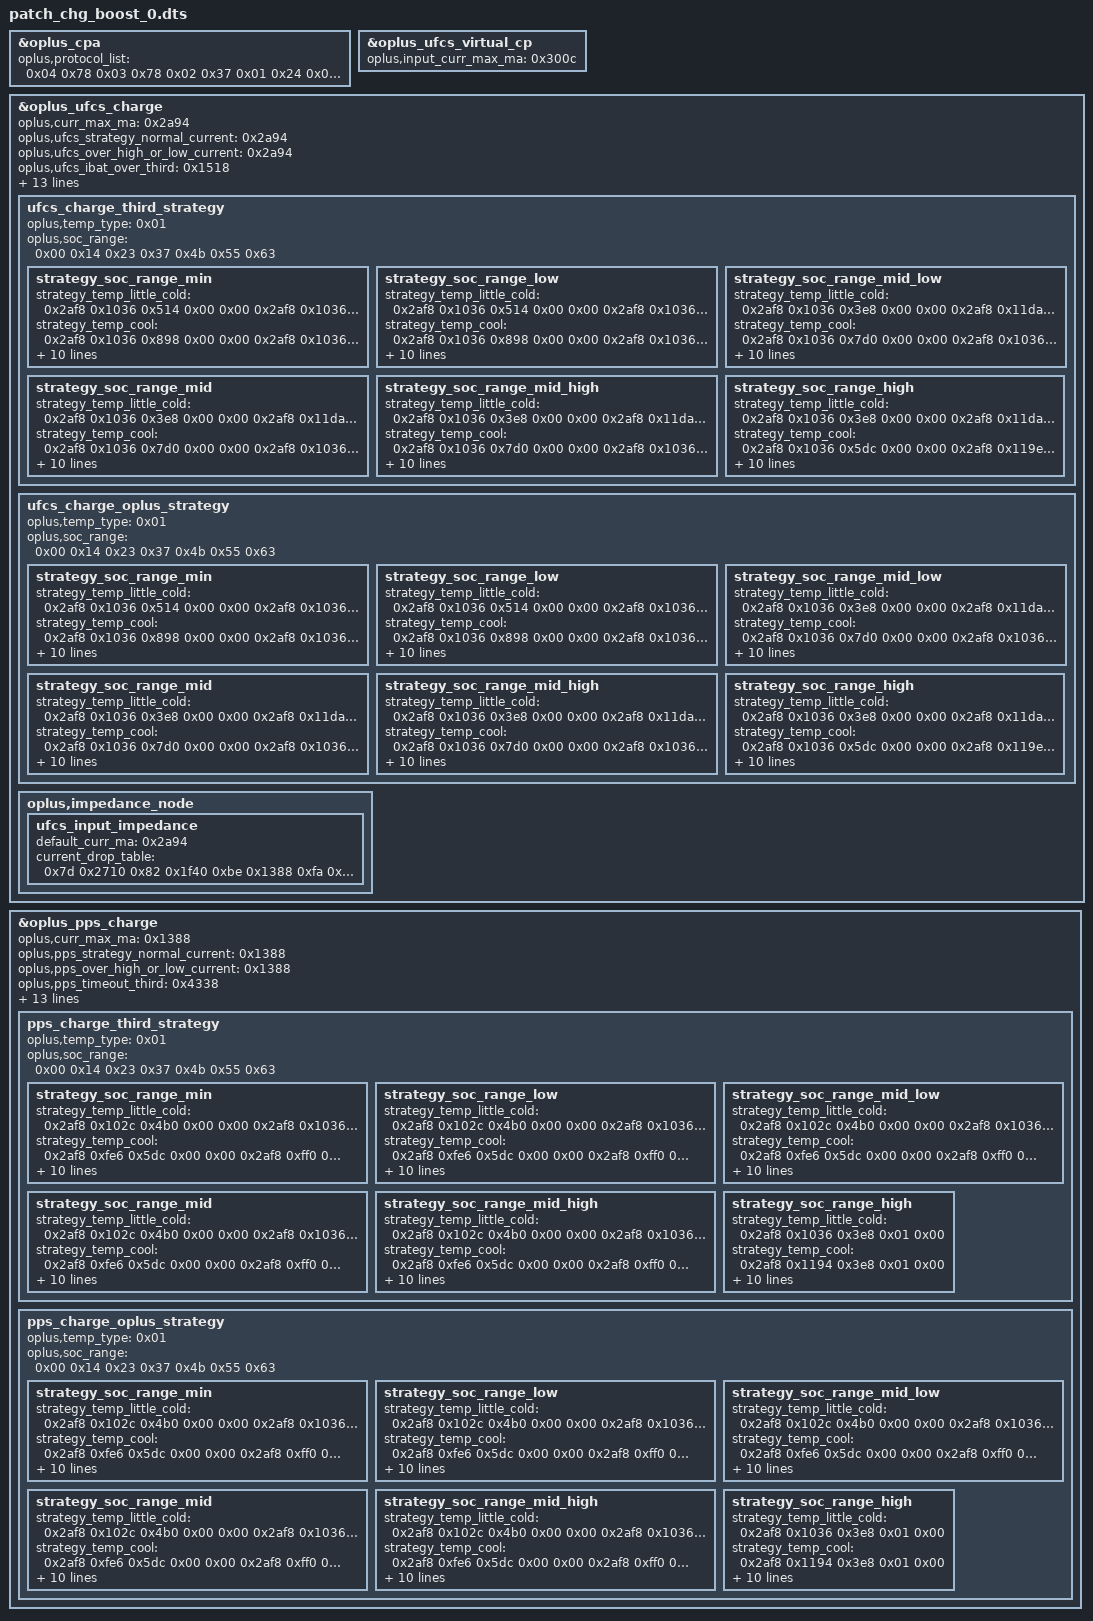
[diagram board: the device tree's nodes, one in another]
/dts-v1/;
/plugin/;

/ {
	fragment@0 {
		target = <&oplus_cpa>;
		__overlay__ {
			oplus,protocol_list = <0x04 0x78 0x03 0x78 0x02 0x37 0x01 0x24 0x05 0x24>;
		};
	};
	
	fragment@1 {
		target = <&oplus_ufcs_virtual_cp>;
		__overlay__ {
			oplus,input_curr_max_ma = <0x300c>;
		};
	};
	
	fragment@2 {
		target = <&oplus_ufcs_charge>;
		__overlay__ {
			oplus,curr_max_ma = <0x2a94>;
			oplus,ufcs_strategy_normal_current = <0x2a94>;
			oplus,ufcs_over_high_or_low_current = <0x2a94>;
			oplus,ufcs_ibat_over_third = <0x1518>;
			oplus,ufcs_ibat_over_oplus = <0x300c>;
			oplus,ufcs_ibus_over_oplus = <0x300c>;
			oplus,ufcs_full_cool_sw_vbat = <0x11da>;
			oplus,ufcs_full_normal_sw_vbat = <0x11da>;
			oplus,ufcs_full_normal_hw_vbat = <0x11e4>;
			oplus,ufcs_full_cool_sw_vbat_third = <0x1194>;
			oplus,ufcs_full_normal_sw_vbat_third = <0x11a8>;
			oplus,ufcs_full_normal_hw_vbat_third = <0x11d0>;
			oplus_spec,ufcs_high_soc = <0x63>;
			oplus,ufcs_strategy_high_current = <0x157c 0xdac 0x7d0 0x2a94 0x157c 0xdac>;
			oplus,ufcs_charge_strategy_soc = <0x00 0x14 0x23 0x37 0x4b 0x55 0x63>;
			
			ufcs_charge_third_strategy {
				oplus,temp_type = <0x01>;
				oplus,soc_range = <0x00 0x14 0x23 0x37 0x4b 0x55 0x63>;
				
				strategy_soc_range_min {
					strategy_temp_little_cold = <0x2af8 0x1036 0x514 0x00 0x00 0x2af8 0x1036 0x3e8 0x00 0x00 0x2af8 0x11da 0x1f4 0x01 0x00>;
					strategy_temp_cool = <0x2af8 0x1036 0x898 0x00 0x00 0x2af8 0x1036 0x7d0 0x00 0x00 0x2af8 0x1036 0x5dc 0x00 0x00 0x2af8 0x119e 0x514 0x00 0x00 0x2af8 0x119e 0x3e8 0x00 0x00 0x2af8 0x11d0 0x2bc 0x00 0x00 0x2af8 0x11da 0x258 0x01 0x00>;
					strategy_temp_little_cool = <0x2af8 0x1036 0xb54 0x00 0x00 0x2af8 0x1036 0x9c4 0x00 0x00 0x2af8 0x10ea 0x898 0x00 0x00 0x2af8 0x10ea 0x7d0 0x00 0x00 0x2af8 0x10ea 0x5dc 0x00 0x00 0x2af8 0x11d0 0x514 0x00 0x00 0x2af8 0x11d0 0x3e8 0x00 0x00 0x2af8 0x11da 0x2bc 0x01 0x00>;
					strategy_temp_little_cool_high = <0x2af8 0x1036 0x16a8 0x00 0x3c 0x2af8 0x1036 0x157c 0x00 0x00 0x2af8 0x1036 0x1388 0x00 0x00 0x2af8 0x1036 0x1194 0x00 0x00 0x2af8 0x10b8 0x10cc 0x00 0x00 0x2af8 0x10b8 0xfa0 0x00 0x00 0x2af8 0x10b8 0xdac 0x00 0x00 0x2af8 0x119e 0xd48 0x00 0x00 0x2af8 0x119e 0xbb8 0x00 0x00 0x2af8 0x11d0 0xb54 0x00 0x00 0x2af8 0x11d0 0x9c4 0x00 0x00 0x2af8 0x11d0 0x7d0 0x00 0x00 0x2af8 0x11d0 0x5dc 0x00 0x00 0x2af8 0x11d0 0x3e8 0x00 0x00 0x2af8 0x11da 0x384 0x01 0x00>;
					strategy_temp_normal_low = <0x2af8 0x1004 0x2a94 0x00 0xa 0x2af8 0x1004 0x238c 0x00 0x32 0x2af8 0x102c 0x21fc 0x00 0x00 0x2af8 0x102c 0x2134 0x00 0x00 0x2af8 0x102c 0x1f40 0x00 0x00 0x2af8 0x1086 0x1e78 0x00 0x00 0x2af8 0x1086 0x1d4c 0x00 0x00 0x2af8 0x1086 0x1b58 0x00 0x00 0x2af8 0x1086 0x1964 0x00 0x00 0x2af8 0x1086 0x1770 0x00 0x00 0x2af8 0x114e 0x16a8 0x00 0x00 0x2af8 0x114e 0x157c 0x00 0x00 0x2af8 0x114e 0x1388 0x00 0x00 0x2af8 0x114e 0x1194 0x00 0x00 0x2af8 0x114e 0xfa0 0x00 0x00 0x2af8 0x114e 0xdac 0x00 0x00 0x2af8 0x11d0 0xd48 0x00 0x00 0x2af8 0x11d0 0xbb8 0x00 0x00 0x2af8 0x11d0 0x9c4 0x00 0x00 0x2af8 0x11d0 0x7d0 0x00 0x00 0x2af8 0x11da 0x5dc 0x01 0x00>;
					strategy_temp_normal_high = <0x2af8 0x1004 0x2a94 0x00 0xa 0x2af8 0x1004 0x238c 0x00 0x32 0x2af8 0x102c 0x21fc 0x00 0x00 0x2af8 0x102c 0x2134 0x00 0x00 0x2af8 0x102c 0x1f40 0x00 0x00 0x2af8 0x1086 0x1e78 0x00 0x00 0x2af8 0x1086 0x1d4c 0x00 0x00 0x2af8 0x1086 0x1b58 0x00 0x00 0x2af8 0x1086 0x1964 0x00 0x00 0x2af8 0x1086 0x1770 0x00 0x00 0x2af8 0x114e 0x16a8 0x00 0x00 0x2af8 0x114e 0x157c 0x00 0x00 0x2af8 0x114e 0x1388 0x00 0x00 0x2af8 0x114e 0x1194 0x00 0x00 0x2af8 0x114e 0xfa0 0x00 0x00 0x2af8 0x114e 0xdac 0x00 0x00 0x2af8 0x11d0 0xd48 0x00 0x00 0x2af8 0x11d0 0xbb8 0x00 0x00 0x2af8 0x11d0 0x9c4 0x00 0x00 0x2af8 0x11da 0x960 0x01 0x00>;
					strategy_temp_warm = <0x2af8 0x1018 0x640 0x00 0x00 0x2af8 0x1018 0x5dc 0x00 0x00 0x2af8 0x1018 0x3e8 0x00 0x00 0x2af8 0x1022 0x1f4 0x01 0x00>;
				};
				
				strategy_soc_range_low {
					strategy_temp_little_cold = <0x2af8 0x1036 0x514 0x00 0x00 0x2af8 0x1036 0x3e8 0x00 0x00 0x2af8 0x11da 0x1f4 0x01 0x00>;
					strategy_temp_cool = <0x2af8 0x1036 0x898 0x00 0x00 0x2af8 0x1036 0x7d0 0x00 0x00 0x2af8 0x1036 0x5dc 0x00 0x00 0x2af8 0x119e 0x514 0x00 0x00 0x2af8 0x119e 0x3e8 0x00 0x00 0x2af8 0x11d0 0x2bc 0x00 0x00 0x2af8 0x11da 0x258 0x01 0x00>;
					strategy_temp_little_cool = <0x2af8 0x1036 0xb54 0x00 0x00 0x2af8 0x1036 0x9c4 0x00 0x00 0x2af8 0x10ea 0x898 0x00 0x00 0x2af8 0x10ea 0x7d0 0x00 0x00 0x2af8 0x10ea 0x5dc 0x00 0x00 0x2af8 0x11d0 0x514 0x00 0x00 0x2af8 0x11d0 0x3e8 0x00 0x00 0x2af8 0x11da 0x2bc 0x01 0x00>;
					strategy_temp_little_cool_high = <0x2af8 0x1036 0x16a8 0x00 0x3c 0x2af8 0x1036 0x157c 0x00 0x00 0x2af8 0x1036 0x1388 0x00 0x00 0x2af8 0x1036 0x1194 0x00 0x00 0x2af8 0x10b8 0x10cc 0x00 0x00 0x2af8 0x10b8 0xfa0 0x00 0x00 0x2af8 0x10b8 0xdac 0x00 0x00 0x2af8 0x119e 0xd48 0x00 0x00 0x2af8 0x119e 0xbb8 0x00 0x00 0x2af8 0x11d0 0xb54 0x00 0x00 0x2af8 0x11d0 0x9c4 0x00 0x00 0x2af8 0x11d0 0x7d0 0x00 0x00 0x2af8 0x11d0 0x5dc 0x00 0x00 0x2af8 0x11d0 0x3e8 0x00 0x00 0x2af8 0x11da 0x384 0x01 0x00>;
					strategy_temp_normal_low = <0x2af8 0x1004 0x238c 0x00 0x3c 0x2af8 0x102c 0x21fc 0x00 0x00 0x2af8 0x102c 0x2134 0x00 0x00 0x2af8 0x102c 0x1f40 0x00 0x00 0x2af8 0x1086 0x1e78 0x00 0x00 0x2af8 0x1086 0x1d4c 0x00 0x00 0x2af8 0x1086 0x1b58 0x00 0x00 0x2af8 0x1086 0x1964 0x00 0x00 0x2af8 0x1086 0x1770 0x00 0x00 0x2af8 0x114e 0x16a8 0x00 0x00 0x2af8 0x114e 0x157c 0x00 0x00 0x2af8 0x114e 0x1388 0x00 0x00 0x2af8 0x114e 0x1194 0x00 0x00 0x2af8 0x114e 0xfa0 0x00 0x00 0x2af8 0x114e 0xdac 0x00 0x00 0x2af8 0x11d0 0xd48 0x00 0x00 0x2af8 0x11d0 0xbb8 0x00 0x00 0x2af8 0x11d0 0x9c4 0x00 0x00 0x2af8 0x11d0 0x7d0 0x00 0x00 0x2af8 0x11da 0x5dc 0x01 0x00>;
					strategy_temp_normal_high = <0x2af8 0x1004 0x238c 0x00 0x3c 0x2af8 0x102c 0x21fc 0x00 0x00 0x2af8 0x102c 0x2134 0x00 0x00 0x2af8 0x102c 0x1f40 0x00 0x00 0x2af8 0x1086 0x1e78 0x00 0x00 0x2af8 0x1086 0x1d4c 0x00 0x00 0x2af8 0x1086 0x1b58 0x00 0x00 0x2af8 0x1086 0x1964 0x00 0x00 0x2af8 0x1086 0x1770 0x00 0x00 0x2af8 0x114e 0x16a8 0x00 0x00 0x2af8 0x114e 0x157c 0x00 0x00 0x2af8 0x114e 0x1388 0x00 0x00 0x2af8 0x114e 0x1194 0x00 0x00 0x2af8 0x114e 0xfa0 0x00 0x00 0x2af8 0x114e 0xdac 0x00 0x00 0x2af8 0x11d0 0xd48 0x00 0x00 0x2af8 0x11d0 0xbb8 0x00 0x00 0x2af8 0x11d0 0x9c4 0x00 0x00 0x2af8 0x11da 0x960 0x01 0x00>;
					strategy_temp_warm = <0x2af8 0x1018 0x640 0x00 0x00 0x2af8 0x1018 0x5dc 0x00 0x00 0x2af8 0x1018 0x3e8 0x00 0x00 0x2af8 0x1022 0x1f4 0x01 0x00>;
				};
				
				strategy_soc_range_mid_low {
					strategy_temp_little_cold = <0x2af8 0x1036 0x3e8 0x00 0x00 0x2af8 0x11da 0x1f4 0x01 0x00>;
					strategy_temp_cool = <0x2af8 0x1036 0x7d0 0x00 0x00 0x2af8 0x1036 0x5dc 0x00 0x00 0x2af8 0x119e 0x514 0x00 0x00 0x2af8 0x119e 0x3e8 0x00 0x00 0x2af8 0x11d0 0x2bc 0x00 0x00 0x2af8 0x11da 0x258 0x01 0x00>;
					strategy_temp_little_cool = <0x2af8 0x1036 0xb54 0x00 0x00 0x2af8 0x1036 0x9c4 0x00 0x00 0x2af8 0x10ea 0x898 0x00 0x00 0x2af8 0x10ea 0x7d0 0x00 0x00 0x2af8 0x10ea 0x5dc 0x00 0x00 0x2af8 0x11d0 0x514 0x00 0x00 0x2af8 0x11d0 0x3e8 0x00 0x00 0x2af8 0x11da 0x2bc 0x01 0x00>;
					strategy_temp_little_cool_high = <0x2af8 0x1036 0x16a8 0x00 0x3c 0x2af8 0x1036 0x157c 0x00 0x00 0x2af8 0x1036 0x1388 0x00 0x00 0x2af8 0x1036 0x1194 0x00 0x00 0x2af8 0x10b8 0x10cc 0x00 0x00 0x2af8 0x10b8 0xfa0 0x00 0x00 0x2af8 0x10b8 0xdac 0x00 0x00 0x2af8 0x119e 0xd48 0x00 0x00 0x2af8 0x119e 0xbb8 0x00 0x00 0x2af8 0x11d0 0xb54 0x00 0x00 0x2af8 0x11d0 0x9c4 0x00 0x00 0x2af8 0x11d0 0x7d0 0x00 0x00 0x2af8 0x11d0 0x5dc 0x00 0x00 0x2af8 0x11d0 0x3e8 0x00 0x00 0x2af8 0x11da 0x384 0x01 0x00>;
					strategy_temp_normal_low = <0x2af8 0x1004 0x238c 0x00 0x3c 0x2af8 0x102c 0x21fc 0x00 0x00 0x2af8 0x102c 0x2134 0x00 0x00 0x2af8 0x102c 0x1f40 0x00 0x00 0x2af8 0x1086 0x1e78 0x00 0x00 0x2af8 0x1086 0x1d4c 0x00 0x00 0x2af8 0x1086 0x1b58 0x00 0x00 0x2af8 0x1086 0x1964 0x00 0x00 0x2af8 0x1086 0x1770 0x00 0x00 0x2af8 0x114e 0x16a8 0x00 0x00 0x2af8 0x114e 0x157c 0x00 0x00 0x2af8 0x114e 0x1388 0x00 0x00 0x2af8 0x114e 0x1194 0x00 0x00 0x2af8 0x114e 0xfa0 0x00 0x00 0x2af8 0x114e 0xdac 0x00 0x00 0x2af8 0x11d0 0xd48 0x00 0x00 0x2af8 0x11d0 0xbb8 0x00 0x00 0x2af8 0x11d0 0x9c4 0x00 0x00 0x2af8 0x11d0 0x7d0 0x00 0x00 0x2af8 0x11da 0x5dc 0x01 0x00>;
					strategy_temp_normal_high = <0x2af8 0x1004 0x238c 0x00 0x3c 0x2af8 0x102c 0x21fc 0x00 0x00 0x2af8 0x102c 0x2134 0x00 0x00 0x2af8 0x102c 0x1f40 0x00 0x00 0x2af8 0x1086 0x1e78 0x00 0x00 0x2af8 0x1086 0x1d4c 0x00 0x00 0x2af8 0x1086 0x1b58 0x00 0x00 0x2af8 0x1086 0x1964 0x00 0x00 0x2af8 0x1086 0x1770 0x00 0x00 0x2af8 0x114e 0x16a8 0x00 0x00 0x2af8 0x114e 0x157c 0x00 0x00 0x2af8 0x114e 0x1388 0x00 0x00 0x2af8 0x114e 0x1194 0x00 0x00 0x2af8 0x114e 0xfa0 0x00 0x00 0x2af8 0x114e 0xdac 0x00 0x00 0x2af8 0x11d0 0xd48 0x00 0x00 0x2af8 0x11d0 0xbb8 0x00 0x00 0x2af8 0x11d0 0x9c4 0x00 0x00 0x2af8 0x11da 0x960 0x01 0x00>;
					strategy_temp_warm = <0x2af8 0x1018 0x640 0x00 0x00 0x2af8 0x1018 0x5dc 0x00 0x00 0x2af8 0x1018 0x3e8 0x00 0x00 0x2af8 0x1022 0x1f4 0x01 0x00>;
				};
				
				strategy_soc_range_mid {
					strategy_temp_little_cold = <0x2af8 0x1036 0x3e8 0x00 0x00 0x2af8 0x11da 0x1f4 0x01 0x00>;
					strategy_temp_cool = <0x2af8 0x1036 0x7d0 0x00 0x00 0x2af8 0x1036 0x5dc 0x00 0x00 0x2af8 0x119e 0x514 0x00 0x00 0x2af8 0x119e 0x3e8 0x00 0x00 0x2af8 0x11d0 0x2bc 0x00 0x00 0x2af8 0x11da 0x258 0x01 0x00>;
					strategy_temp_little_cool = <0x2af8 0x1036 0xb54 0x00 0x00 0x2af8 0x1036 0x9c4 0x00 0x00 0x2af8 0x10ea 0x898 0x00 0x00 0x2af8 0x10ea 0x7d0 0x00 0x00 0x2af8 0x10ea 0x5dc 0x00 0x00 0x2af8 0x11d0 0x514 0x00 0x00 0x2af8 0x11d0 0x3e8 0x00 0x00 0x2af8 0x11da 0x2bc 0x01 0x00>;
					strategy_temp_little_cool_high = <0x2af8 0x10b8 0xfa0 0x00 0x00 0x2af8 0x10b8 0xdac 0x00 0x00 0x2af8 0x119e 0xd48 0x00 0x00 0x2af8 0x119e 0xbb8 0x00 0x00 0x2af8 0x11d0 0xb54 0x00 0x00 0x2af8 0x11d0 0x9c4 0x00 0x00 0x2af8 0x11d0 0x7d0 0x00 0x00 0x2af8 0x11d0 0x5dc 0x00 0x00 0x2af8 0x11d0 0x3e8 0x00 0x00 0x2af8 0x11da 0x384 0x01 0x00>;
					strategy_temp_normal_low = <0x2af8 0x114e 0x1194 0x00 0x00 0x2af8 0x114e 0xfa0 0x00 0x00 0x2af8 0x114e 0xdac 0x00 0x00 0x2af8 0x11d0 0xd48 0x00 0x00 0x2af8 0x11d0 0xbb8 0x00 0x00 0x2af8 0x11d0 0x9c4 0x00 0x00 0x2af8 0x11d0 0x7d0 0x00 0x00 0x2af8 0x11da 0x5dc 0x01 0x00>;
					strategy_temp_normal_high = <0x2af8 0x114e 0x1388 0x00 0x00 0x2af8 0x114e 0x1194 0x00 0x00 0x2af8 0x114e 0xfa0 0x00 0x00 0x2af8 0x114e 0xdac 0x00 0x00 0x2af8 0x11d0 0xd48 0x00 0x00 0x2af8 0x11d0 0xbb8 0x00 0x00 0x2af8 0x11d0 0x9c4 0x00 0x00 0x2af8 0x11da 0x960 0x01 0x00>;
					strategy_temp_warm = <0x2af8 0x1022 0x3e8 0x01 0x00>;
				};
				
				strategy_soc_range_mid_high {
					strategy_temp_little_cold = <0x2af8 0x1036 0x3e8 0x00 0x00 0x2af8 0x11da 0x1f4 0x01 0x00>;
					strategy_temp_cool = <0x2af8 0x1036 0x7d0 0x00 0x00 0x2af8 0x1036 0x5dc 0x00 0x00 0x2af8 0x119e 0x514 0x00 0x00 0x2af8 0x119e 0x3e8 0x00 0x00 0x2af8 0x11d0 0x2bc 0x00 0x00 0x2af8 0x11da 0x258 0x01 0x00>;
					strategy_temp_little_cool = <0x2af8 0x1036 0xb54 0x00 0x00 0x2af8 0x1036 0x9c4 0x00 0x00 0x2af8 0x10ea 0x898 0x00 0x00 0x2af8 0x10ea 0x7d0 0x00 0x00 0x2af8 0x10ea 0x5dc 0x00 0x00 0x2af8 0x11d0 0x514 0x00 0x00 0x2af8 0x11d0 0x3e8 0x00 0x00 0x2af8 0x11da 0x2bc 0x01 0x00>;
					strategy_temp_little_cool_high = <0x2af8 0x119e 0xbb8 0x00 0x00 0x2af8 0x11d0 0xb54 0x00 0x00 0x2af8 0x11d0 0x9c4 0x00 0x00 0x2af8 0x11d0 0x7d0 0x00 0x00 0x2af8 0x11d0 0x5dc 0x00 0x00 0x2af8 0x11d0 0x3e8 0x00 0x00 0x2af8 0x11da 0x384 0x01 0x00>;
					strategy_temp_normal_low = <0x2af8 0x114e 0xdac 0x00 0x00 0x2af8 0x11d0 0xd48 0x00 0x00 0x2af8 0x11d0 0xbb8 0x00 0x00 0x2af8 0x11d0 0x9c4 0x00 0x00 0x2af8 0x11d0 0x7d0 0x00 0x00 0x2af8 0x11da 0x5dc 0x01 0x00>;
					strategy_temp_normal_high = <0x2af8 0x114e 0xdac 0x00 0x00 0x2af8 0x11d0 0xd48 0x00 0x00 0x2af8 0x11d0 0xbb8 0x00 0x00 0x2af8 0x11d0 0x9c4 0x00 0x00 0x2af8 0x11da 0x960 0x01 0x00>;
					strategy_temp_warm = <0x2af8 0x1022 0x3e8 0x01 0x00>;
				};
				
				strategy_soc_range_high {
					strategy_temp_little_cold = <0x2af8 0x1036 0x3e8 0x00 0x00 0x2af8 0x11da 0x1f4 0x01 0x00>;
					strategy_temp_cool = <0x2af8 0x1036 0x5dc 0x00 0x00 0x2af8 0x119e 0x514 0x00 0x00 0x2af8 0x119e 0x3e8 0x00 0x00 0x2af8 0x11d0 0x2bc 0x00 0x00 0x2af8 0x11da 0x258 0x01 0x00>;
					strategy_temp_little_cool = <0x2af8 0x10ea 0x5dc 0x00 0x00 0x2af8 0x11d0 0x514 0x00 0x00 0x2af8 0x11d0 0x3e8 0x00 0x00 0x2af8 0x11da 0x2bc 0x01 0x00>;
					strategy_temp_little_cool_high = <0x2af8 0x11d0 0x5dc 0x00 0x00 0x2af8 0x11d0 0x3e8 0x00 0x00 0x2af8 0x11da 0x384 0x01 0x00>;
					strategy_temp_normal_low = <0x2af8 0x11d0 0x7d0 0x00 0x00 0x2af8 0x11da 0x5dc 0x01 0x00>;
					strategy_temp_normal_high = <0x2af8 0x11da 0x960 0x01 0x00>;
					strategy_temp_warm = <0x2af8 0x1022 0x3e8 0x01 0x00>;
				};
			};
			
			ufcs_charge_oplus_strategy {
				oplus,temp_type = <0x01>;
				oplus,soc_range = <0x00 0x14 0x23 0x37 0x4b 0x55 0x63>;
				
				strategy_soc_range_min {
					strategy_temp_little_cold = <0x2af8 0x1036 0x514 0x00 0x00 0x2af8 0x1036 0x3e8 0x00 0x00 0x2af8 0x11da 0x1f4 0x01 0x00>;
					strategy_temp_cool = <0x2af8 0x1036 0x898 0x00 0x00 0x2af8 0x1036 0x7d0 0x00 0x00 0x2af8 0x1036 0x5dc 0x00 0x00 0x2af8 0x119e 0x514 0x00 0x00 0x2af8 0x119e 0x3e8 0x00 0x00 0x2af8 0x11d0 0x2bc 0x00 0x00 0x2af8 0x11da 0x258 0x01 0x00>;
					strategy_temp_little_cool = <0x2af8 0x1036 0xb54 0x00 0x00 0x2af8 0x1036 0x9c4 0x00 0x00 0x2af8 0x10ea 0x898 0x00 0x00 0x2af8 0x10ea 0x7d0 0x00 0x00 0x2af8 0x10ea 0x5dc 0x00 0x00 0x2af8 0x11d0 0x514 0x00 0x00 0x2af8 0x11d0 0x3e8 0x00 0x00 0x2af8 0x11da 0x2bc 0x01 0x00>;
					strategy_temp_little_cool_high = <0x2af8 0x1036 0x16a8 0x00 0x3c 0x2af8 0x1036 0x157c 0x00 0x00 0x2af8 0x1036 0x1388 0x00 0x00 0x2af8 0x1036 0x1194 0x00 0x00 0x2af8 0x10b8 0x10cc 0x00 0x00 0x2af8 0x10b8 0xfa0 0x00 0x00 0x2af8 0x10b8 0xdac 0x00 0x00 0x2af8 0x119e 0xd48 0x00 0x00 0x2af8 0x119e 0xbb8 0x00 0x00 0x2af8 0x11d0 0xb54 0x00 0x00 0x2af8 0x11d0 0x9c4 0x00 0x00 0x2af8 0x11d0 0x7d0 0x00 0x00 0x2af8 0x11d0 0x5dc 0x00 0x00 0x2af8 0x11d0 0x3e8 0x00 0x00 0x2af8 0x11da 0x384 0x01 0x00>;
					strategy_temp_normal_low = <0x2af8 0x1004 0x2a94 0x00 0xa 0x2af8 0x1004 0x238c 0x00 0x32 0x2af8 0x102c 0x21fc 0x00 0x00 0x2af8 0x102c 0x2134 0x00 0x00 0x2af8 0x102c 0x1f40 0x00 0x00 0x2af8 0x1086 0x1e78 0x00 0x00 0x2af8 0x1086 0x1d4c 0x00 0x00 0x2af8 0x1086 0x1b58 0x00 0x00 0x2af8 0x1086 0x1964 0x00 0x00 0x2af8 0x1086 0x1770 0x00 0x00 0x2af8 0x114e 0x16a8 0x00 0x00 0x2af8 0x114e 0x157c 0x00 0x00 0x2af8 0x114e 0x1388 0x00 0x00 0x2af8 0x114e 0x1194 0x00 0x00 0x2af8 0x114e 0xfa0 0x00 0x00 0x2af8 0x114e 0xdac 0x00 0x00 0x2af8 0x11d0 0xd48 0x00 0x00 0x2af8 0x11d0 0xbb8 0x00 0x00 0x2af8 0x11d0 0x9c4 0x00 0x00 0x2af8 0x11d0 0x7d0 0x00 0x00 0x2af8 0x11da 0x5dc 0x01 0x00>;
					strategy_temp_normal_high = <0x2af8 0x1004 0x2a94 0x00 0xa 0x2af8 0x1004 0x238c 0x00 0x32 0x2af8 0x102c 0x21fc 0x00 0x00 0x2af8 0x102c 0x2134 0x00 0x00 0x2af8 0x102c 0x1f40 0x00 0x00 0x2af8 0x1086 0x1e78 0x00 0x00 0x2af8 0x1086 0x1d4c 0x00 0x00 0x2af8 0x1086 0x1b58 0x00 0x00 0x2af8 0x1086 0x1964 0x00 0x00 0x2af8 0x1086 0x1770 0x00 0x00 0x2af8 0x114e 0x16a8 0x00 0x00 0x2af8 0x114e 0x157c 0x00 0x00 0x2af8 0x114e 0x1388 0x00 0x00 0x2af8 0x114e 0x1194 0x00 0x00 0x2af8 0x114e 0xfa0 0x00 0x00 0x2af8 0x114e 0xdac 0x00 0x00 0x2af8 0x11d0 0xd48 0x00 0x00 0x2af8 0x11d0 0xbb8 0x00 0x00 0x2af8 0x11d0 0x9c4 0x00 0x00 0x2af8 0x11da 0x960 0x01 0x00>;
					strategy_temp_warm = <0x2af8 0x1018 0x640 0x00 0x00 0x2af8 0x1018 0x5dc 0x00 0x00 0x2af8 0x1018 0x3e8 0x00 0x00 0x2af8 0x1022 0x1f4 0x01 0x00>;
				};
				
				strategy_soc_range_low {
					strategy_temp_little_cold = <0x2af8 0x1036 0x514 0x00 0x00 0x2af8 0x1036 0x3e8 0x00 0x00 0x2af8 0x11da 0x1f4 0x01 0x00>;
					strategy_temp_cool = <0x2af8 0x1036 0x898 0x00 0x00 0x2af8 0x1036 0x7d0 0x00 0x00 0x2af8 0x1036 0x5dc 0x00 0x00 0x2af8 0x119e 0x514 0x00 0x00 0x2af8 0x119e 0x3e8 0x00 0x00 0x2af8 0x11d0 0x2bc 0x00 0x00 0x2af8 0x11da 0x258 0x01 0x00>;
					strategy_temp_little_cool = <0x2af8 0x1036 0xb54 0x00 0x00 0x2af8 0x1036 0x9c4 0x00 0x00 0x2af8 0x10ea 0x898 0x00 0x00 0x2af8 0x10ea 0x7d0 0x00 0x00 0x2af8 0x10ea 0x5dc 0x00 0x00 0x2af8 0x11d0 0x514 0x00 0x00 0x2af8 0x11d0 0x3e8 0x00 0x00 0x2af8 0x11da 0x2bc 0x01 0x00>;
					strategy_temp_little_cool_high = <0x2af8 0x1036 0x16a8 0x00 0x3c 0x2af8 0x1036 0x157c 0x00 0x00 0x2af8 0x1036 0x1388 0x00 0x00 0x2af8 0x1036 0x1194 0x00 0x00 0x2af8 0x10b8 0x10cc 0x00 0x00 0x2af8 0x10b8 0xfa0 0x00 0x00 0x2af8 0x10b8 0xdac 0x00 0x00 0x2af8 0x119e 0xd48 0x00 0x00 0x2af8 0x119e 0xbb8 0x00 0x00 0x2af8 0x11d0 0xb54 0x00 0x00 0x2af8 0x11d0 0x9c4 0x00 0x00 0x2af8 0x11d0 0x7d0 0x00 0x00 0x2af8 0x11d0 0x5dc 0x00 0x00 0x2af8 0x11d0 0x3e8 0x00 0x00 0x2af8 0x11da 0x384 0x01 0x00>;
					strategy_temp_normal_low = <0x2af8 0x1004 0x238c 0x00 0x3c 0x2af8 0x102c 0x21fc 0x00 0x00 0x2af8 0x102c 0x2134 0x00 0x00 0x2af8 0x102c 0x1f40 0x00 0x00 0x2af8 0x1086 0x1e78 0x00 0x00 0x2af8 0x1086 0x1d4c 0x00 0x00 0x2af8 0x1086 0x1b58 0x00 0x00 0x2af8 0x1086 0x1964 0x00 0x00 0x2af8 0x1086 0x1770 0x00 0x00 0x2af8 0x114e 0x16a8 0x00 0x00 0x2af8 0x114e 0x157c 0x00 0x00 0x2af8 0x114e 0x1388 0x00 0x00 0x2af8 0x114e 0x1194 0x00 0x00 0x2af8 0x114e 0xfa0 0x00 0x00 0x2af8 0x114e 0xdac 0x00 0x00 0x2af8 0x11d0 0xd48 0x00 0x00 0x2af8 0x11d0 0xbb8 0x00 0x00 0x2af8 0x11d0 0x9c4 0x00 0x00 0x2af8 0x11d0 0x7d0 0x00 0x00 0x2af8 0x11da 0x5dc 0x01 0x00>;
					strategy_temp_normal_high = <0x2af8 0x1004 0x238c 0x00 0x3c 0x2af8 0x102c 0x21fc 0x00 0x00 0x2af8 0x102c 0x2134 0x00 0x00 0x2af8 0x102c 0x1f40 0x00 0x00 0x2af8 0x1086 0x1e78 0x00 0x00 0x2af8 0x1086 0x1d4c 0x00 0x00 0x2af8 0x1086 0x1b58 0x00 0x00 0x2af8 0x1086 0x1964 0x00 0x00 0x2af8 0x1086 0x1770 0x00 0x00 0x2af8 0x114e 0x16a8 0x00 0x00 0x2af8 0x114e 0x157c 0x00 0x00 0x2af8 0x114e 0x1388 0x00 0x00 0x2af8 0x114e 0x1194 0x00 0x00 0x2af8 0x114e 0xfa0 0x00 0x00 0x2af8 0x114e 0xdac 0x00 0x00 0x2af8 0x11d0 0xd48 0x00 0x00 0x2af8 0x11d0 0xbb8 0x00 0x00 0x2af8 0x11d0 0x9c4 0x00 0x00 0x2af8 0x11da 0x960 0x01 0x00>;
					strategy_temp_warm = <0x2af8 0x1018 0x640 0x00 0x00 0x2af8 0x1018 0x5dc 0x00 0x00 0x2af8 0x1018 0x3e8 0x00 0x00 0x2af8 0x1022 0x1f4 0x01 0x00>;
				};
				
				strategy_soc_range_mid_low {
					strategy_temp_little_cold = <0x2af8 0x1036 0x3e8 0x00 0x00 0x2af8 0x11da 0x1f4 0x01 0x00>;
					strategy_temp_cool = <0x2af8 0x1036 0x7d0 0x00 0x00 0x2af8 0x1036 0x5dc 0x00 0x00 0x2af8 0x119e 0x514 0x00 0x00 0x2af8 0x119e 0x3e8 0x00 0x00 0x2af8 0x11d0 0x2bc 0x00 0x00 0x2af8 0x11da 0x258 0x01 0x00>;
					strategy_temp_little_cool = <0x2af8 0x1036 0xb54 0x00 0x00 0x2af8 0x1036 0x9c4 0x00 0x00 0x2af8 0x10ea 0x898 0x00 0x00 0x2af8 0x10ea 0x7d0 0x00 0x00 0x2af8 0x10ea 0x5dc 0x00 0x00 0x2af8 0x11d0 0x514 0x00 0x00 0x2af8 0x11d0 0x3e8 0x00 0x00 0x2af8 0x11da 0x2bc 0x01 0x00>;
					strategy_temp_little_cool_high = <0x2af8 0x1036 0x16a8 0x00 0x3c 0x2af8 0x1036 0x157c 0x00 0x00 0x2af8 0x1036 0x1388 0x00 0x00 0x2af8 0x1036 0x1194 0x00 0x00 0x2af8 0x10b8 0x10cc 0x00 0x00 0x2af8 0x10b8 0xfa0 0x00 0x00 0x2af8 0x10b8 0xdac 0x00 0x00 0x2af8 0x119e 0xd48 0x00 0x00 0x2af8 0x119e 0xbb8 0x00 0x00 0x2af8 0x11d0 0xb54 0x00 0x00 0x2af8 0x11d0 0x9c4 0x00 0x00 0x2af8 0x11d0 0x7d0 0x00 0x00 0x2af8 0x11d0 0x5dc 0x00 0x00 0x2af8 0x11d0 0x3e8 0x00 0x00 0x2af8 0x11da 0x384 0x01 0x00>;
					strategy_temp_normal_low = <0x2af8 0x1004 0x238c 0x00 0x3c 0x2af8 0x102c 0x21fc 0x00 0x00 0x2af8 0x102c 0x2134 0x00 0x00 0x2af8 0x102c 0x1f40 0x00 0x00 0x2af8 0x1086 0x1e78 0x00 0x00 0x2af8 0x1086 0x1d4c 0x00 0x00 0x2af8 0x1086 0x1b58 0x00 0x00 0x2af8 0x1086 0x1964 0x00 0x00 0x2af8 0x1086 0x1770 0x00 0x00 0x2af8 0x114e 0x16a8 0x00 0x00 0x2af8 0x114e 0x157c 0x00 0x00 0x2af8 0x114e 0x1388 0x00 0x00 0x2af8 0x114e 0x1194 0x00 0x00 0x2af8 0x114e 0xfa0 0x00 0x00 0x2af8 0x114e 0xdac 0x00 0x00 0x2af8 0x11d0 0xd48 0x00 0x00 0x2af8 0x11d0 0xbb8 0x00 0x00 0x2af8 0x11d0 0x9c4 0x00 0x00 0x2af8 0x11d0 0x7d0 0x00 0x00 0x2af8 0x11da 0x5dc 0x01 0x00>;
					strategy_temp_normal_high = <0x2af8 0x1004 0x238c 0x00 0x3c 0x2af8 0x102c 0x21fc 0x00 0x00 0x2af8 0x102c 0x2134 0x00 0x00 0x2af8 0x102c 0x1f40 0x00 0x00 0x2af8 0x1086 0x1e78 0x00 0x00 0x2af8 0x1086 0x1d4c 0x00 0x00 0x2af8 0x1086 0x1b58 0x00 0x00 0x2af8 0x1086 0x1964 0x00 0x00 0x2af8 0x1086 0x1770 0x00 0x00 0x2af8 0x114e 0x16a8 0x00 0x00 0x2af8 0x114e 0x157c 0x00 0x00 0x2af8 0x114e 0x1388 0x00 0x00 0x2af8 0x114e 0x1194 0x00 0x00 0x2af8 0x114e 0xfa0 0x00 0x00 0x2af8 0x114e 0xdac 0x00 0x00 0x2af8 0x11d0 0xd48 0x00 0x00 0x2af8 0x11d0 0xbb8 0x00 0x00 0x2af8 0x11d0 0x9c4 0x00 0x00 0x2af8 0x11da 0x960 0x01 0x00>;
					strategy_temp_warm = <0x2af8 0x1018 0x640 0x00 0x00 0x2af8 0x1018 0x5dc 0x00 0x00 0x2af8 0x1018 0x3e8 0x00 0x00 0x2af8 0x1022 0x1f4 0x01 0x00>;
				};
				
				strategy_soc_range_mid {
					strategy_temp_little_cold = <0x2af8 0x1036 0x3e8 0x00 0x00 0x2af8 0x11da 0x1f4 0x01 0x00>;
					strategy_temp_cool = <0x2af8 0x1036 0x7d0 0x00 0x00 0x2af8 0x1036 0x5dc 0x00 0x00 0x2af8 0x119e 0x514 0x00 0x00 0x2af8 0x119e 0x3e8 0x00 0x00 0x2af8 0x11d0 0x2bc 0x00 0x00 0x2af8 0x11da 0x258 0x01 0x00>;
					strategy_temp_little_cool = <0x2af8 0x1036 0xb54 0x00 0x00 0x2af8 0x1036 0x9c4 0x00 0x00 0x2af8 0x10ea 0x898 0x00 0x00 0x2af8 0x10ea 0x7d0 0x00 0x00 0x2af8 0x10ea 0x5dc 0x00 0x00 0x2af8 0x11d0 0x514 0x00 0x00 0x2af8 0x11d0 0x3e8 0x00 0x00 0x2af8 0x11da 0x2bc 0x01 0x00>;
					strategy_temp_little_cool_high = <0x2af8 0x10b8 0xfa0 0x00 0x00 0x2af8 0x10b8 0xdac 0x00 0x00 0x2af8 0x119e 0xd48 0x00 0x00 0x2af8 0x119e 0xbb8 0x00 0x00 0x2af8 0x11d0 0xb54 0x00 0x00 0x2af8 0x11d0 0x9c4 0x00 0x00 0x2af8 0x11d0 0x7d0 0x00 0x00 0x2af8 0x11d0 0x5dc 0x00 0x00 0x2af8 0x11d0 0x3e8 0x00 0x00 0x2af8 0x11da 0x384 0x01 0x00>;
					strategy_temp_normal_low = <0x2af8 0x114e 0x1194 0x00 0x00 0x2af8 0x114e 0xfa0 0x00 0x00 0x2af8 0x114e 0xdac 0x00 0x00 0x2af8 0x11d0 0xd48 0x00 0x00 0x2af8 0x11d0 0xbb8 0x00 0x00 0x2af8 0x11d0 0x9c4 0x00 0x00 0x2af8 0x11d0 0x7d0 0x00 0x00 0x2af8 0x11da 0x5dc 0x01 0x00>;
					strategy_temp_normal_high = <0x2af8 0x114e 0x1388 0x00 0x00 0x2af8 0x114e 0x1194 0x00 0x00 0x2af8 0x114e 0xfa0 0x00 0x00 0x2af8 0x114e 0xdac 0x00 0x00 0x2af8 0x11d0 0xd48 0x00 0x00 0x2af8 0x11d0 0xbb8 0x00 0x00 0x2af8 0x11d0 0x9c4 0x00 0x00 0x2af8 0x11da 0x960 0x01 0x00>;
					strategy_temp_warm = <0x2af8 0x1022 0x3e8 0x01 0x00>;
				};
				
				strategy_soc_range_mid_high {
					strategy_temp_little_cold = <0x2af8 0x1036 0x3e8 0x00 0x00 0x2af8 0x11da 0x1f4 0x01 0x00>;
					strategy_temp_cool = <0x2af8 0x1036 0x7d0 0x00 0x00 0x2af8 0x1036 0x5dc 0x00 0x00 0x2af8 0x119e 0x514 0x00 0x00 0x2af8 0x119e 0x3e8 0x00 0x00 0x2af8 0x11d0 0x2bc 0x00 0x00 0x2af8 0x11da 0x258 0x01 0x00>;
					strategy_temp_little_cool = <0x2af8 0x1036 0xb54 0x00 0x00 0x2af8 0x1036 0x9c4 0x00 0x00 0x2af8 0x10ea 0x898 0x00 0x00 0x2af8 0x10ea 0x7d0 0x00 0x00 0x2af8 0x10ea 0x5dc 0x00 0x00 0x2af8 0x11d0 0x514 0x00 0x00 0x2af8 0x11d0 0x3e8 0x00 0x00 0x2af8 0x11da 0x2bc 0x01 0x00>;
					strategy_temp_little_cool_high = <0x2af8 0x119e 0xbb8 0x00 0x00 0x2af8 0x11d0 0xb54 0x00 0x00 0x2af8 0x11d0 0x9c4 0x00 0x00 0x2af8 0x11d0 0x7d0 0x00 0x00 0x2af8 0x11d0 0x5dc 0x00 0x00 0x2af8 0x11d0 0x3e8 0x00 0x00 0x2af8 0x11da 0x384 0x01 0x00>;
					strategy_temp_normal_low = <0x2af8 0x114e 0xdac 0x00 0x00 0x2af8 0x11d0 0xd48 0x00 0x00 0x2af8 0x11d0 0xbb8 0x00 0x00 0x2af8 0x11d0 0x9c4 0x00 0x00 0x2af8 0x11d0 0x7d0 0x00 0x00 0x2af8 0x11da 0x5dc 0x01 0x00>;
					strategy_temp_normal_high = <0x2af8 0x114e 0xdac 0x00 0x00 0x2af8 0x11d0 0xd48 0x00 0x00 0x2af8 0x11d0 0xbb8 0x00 0x00 0x2af8 0x11d0 0x9c4 0x00 0x00 0x2af8 0x11da 0x960 0x01 0x00>;
					strategy_temp_warm = <0x2af8 0x1022 0x3e8 0x01 0x00>;
				};
				
				strategy_soc_range_high {
					strategy_temp_little_cold = <0x2af8 0x1036 0x3e8 0x00 0x00 0x2af8 0x11da 0x1f4 0x01 0x00>;
					strategy_temp_cool = <0x2af8 0x1036 0x5dc 0x00 0x00 0x2af8 0x119e 0x514 0x00 0x00 0x2af8 0x119e 0x3e8 0x00 0x00 0x2af8 0x11d0 0x2bc 0x00 0x00 0x2af8 0x11da 0x258 0x01 0x00>;
					strategy_temp_little_cool = <0x2af8 0x10ea 0x5dc 0x00 0x00 0x2af8 0x11d0 0x514 0x00 0x00 0x2af8 0x11d0 0x3e8 0x00 0x00 0x2af8 0x11da 0x2bc 0x01 0x00>;
					strategy_temp_little_cool_high = <0x2af8 0x11d0 0x5dc 0x00 0x00 0x2af8 0x11d0 0x3e8 0x00 0x00 0x2af8 0x11da 0x384 0x01 0x00>;
					strategy_temp_normal_low = <0x2af8 0x11d0 0x7d0 0x00 0x00 0x2af8 0x11da 0x5dc 0x01 0x00>;
					strategy_temp_normal_high = <0x2af8 0x11da 0x960 0x01 0x00>;
					strategy_temp_warm = <0x2af8 0x1022 0x3e8 0x01 0x00>;
				};
			};
			
			oplus,impedance_node {
				
				ufcs_input_impedance {
					default_curr_ma = <0x2a94>;
					current_drop_table = <0x7d 0x2710 0x82 0x1f40 0xbe 0x1388 0xfa 0xfa0 0x154 0xbb8 0x17c 0x7d0 0x1e0 0x00>;
				};
			};
		};
	};
	
	fragment@3 {
		target = <&oplus_pps_charge>;
		__overlay__ {
			oplus,curr_max_ma = <0x1388>;
			oplus,pps_strategy_normal_current = <0x1388>;
			oplus,pps_over_high_or_low_current = <0x1388>;
			oplus,pps_timeout_third = <0x4338>;
			oplus,pps_timeout_oplus = <0x4338>;
			oplus,pps_ibat_over_third = <0x1900>;
			oplus,pps_ibat_over_oplus = <0x1900>;
			oplus,pps_full_cool_sw_vbat = <0x1194>;
			oplus,pps_full_normal_sw_vbat = <0x11a8>;
			oplus,pps_full_normal_hw_vbat = <0x11d0>;
			oplus,pps_full_cool_sw_vbat_third = <0x1194>;
			oplus,pps_full_normal_sw_vbat_third = <0x11a8>;
			oplus,pps_full_normal_hw_vbat_third = <0x11d0>;
			oplus,pps_strategy_high_current = <0x1388 0xfa0 0xbb8 0x1388 0x1388 0xfa0>;
			oplus,pps_charge_strategy_soc = <0x00 0x14 0x23 0x37 0x4b 0x55 0x63>;
			
			pps_charge_third_strategy {
				oplus,temp_type = <0x01>;
				oplus,soc_range = <0x00 0x14 0x23 0x37 0x4b 0x55 0x63>;
				
				strategy_soc_range_min {
					strategy_temp_little_cold = <0x2af8 0x102c 0x4b0 0x00 0x00 0x2af8 0x1036 0x3e8 0x01 0x00>;
					strategy_temp_cool = <0x2af8 0xfe6 0x5dc 0x00 0x00 0x2af8 0xff0 0x3e8 0x01 0x00>;
					strategy_temp_little_cool = <0x2af8 0xff0 0xc80 0x00 0x00 0x2af8 0xff0 0xbb8 0x00 0x00 0x2af8 0xff0 0x9c4 0x00 0x00 0x2af8 0xff0 0x7d0 0x00 0x00 0x2af8 0x104a 0x5dc 0x00 0x00 0x2af8 0x1054 0x3e8 0x01 0x00>;
					strategy_temp_little_cool_high = <0x2af8 0xff0 0xed8 0x00 0x00 0x2af8 0xff0 0xdac 0x00 0x00 0x2af8 0x1054 0xc80 0x00 0x00 0x2af8 0x1054 0xbb8 0x00 0x00 0x2af8 0x1054 0x9c4 0x00 0x00 0x2af8 0x1054 0x7d0 0x00 0x00 0x2af8 0x119e 0x5dc 0x00 0x00 0x2af8 0x11a8 0x3e8 0x01 0x00>;
					strategy_temp_normal_low = <0x2af8 0x119e 0x1388 0x00 0x00 0x2af8 0x119e 0x12c0 0x00 0x00 0x2af8 0x119e 0x1194 0x00 0x00 0x2af8 0x119e 0xfa0 0x00 0x00 0x2af8 0x119e 0xdac 0x00 0x00 0x2af8 0x119e 0xbb8 0x00 0x00 0x2af8 0x119e 0x9c4 0x00 0x00 0x2af8 0x119e 0x7d0 0x00 0x00 0x2af8 0x119e 0x5dc 0x00 0x00 0x2af8 0x11a8 0x3e8 0x01 0x00>;
					strategy_temp_normal_high = <0x2af8 0x118a 0x1388 0x00 0x00 0x2af8 0x118a 0x12c0 0x00 0x00 0x2af8 0x118a 0x1194 0x00 0x00 0x2af8 0x118a 0xfa0 0x00 0x00 0x2af8 0x118a 0xdac 0x00 0x00 0x2af8 0x118a 0xbb8 0x00 0x00 0x2af8 0x118a 0x9c4 0x00 0x00 0x2af8 0x118a 0x7d0 0x00 0x00 0x2af8 0x118a 0x5dc 0x00 0x00 0x2af8 0x1194 0x3e8 0x01 0x00>;
					strategy_temp_warm = <0x2af8 0x1018 0x708 0x00 0x00 0x2af8 0x1018 0x5dc 0x00 0x00 0x2af8 0x1022 0x3e8 0x01 0x00>;
				};
				
				strategy_soc_range_low {
					strategy_temp_little_cold = <0x2af8 0x102c 0x4b0 0x00 0x00 0x2af8 0x1036 0x3e8 0x01 0x00>;
					strategy_temp_cool = <0x2af8 0xfe6 0x5dc 0x00 0x00 0x2af8 0xff0 0x3e8 0x01 0x00>;
					strategy_temp_little_cool = <0x2af8 0xff0 0xc80 0x00 0x00 0x2af8 0xff0 0xbb8 0x00 0x00 0x2af8 0xff0 0x9c4 0x00 0x00 0x2af8 0xff0 0x7d0 0x00 0x00 0x2af8 0x104a 0x5dc 0x00 0x00 0x2af8 0x1054 0x3e8 0x01 0x00>;
					strategy_temp_little_cool_high = <0x2af8 0xff0 0xed8 0x00 0x00 0x2af8 0xff0 0xdac 0x00 0x00 0x2af8 0x1054 0xc80 0x00 0x00 0x2af8 0x1054 0xbb8 0x00 0x00 0x2af8 0x1054 0x9c4 0x00 0x00 0x2af8 0x1054 0x7d0 0x00 0x00 0x2af8 0x119e 0x5dc 0x00 0x00 0x2af8 0x11a8 0x3e8 0x01 0x00>;
					strategy_temp_normal_low = <0x2af8 0x119e 0x1388 0x00 0x00 0x2af8 0x119e 0x12c0 0x00 0x00 0x2af8 0x119e 0x1194 0x00 0x00 0x2af8 0x119e 0xfa0 0x00 0x00 0x2af8 0x119e 0xdac 0x00 0x00 0x2af8 0x119e 0xbb8 0x00 0x00 0x2af8 0x119e 0x9c4 0x00 0x00 0x2af8 0x119e 0x7d0 0x00 0x00 0x2af8 0x119e 0x5dc 0x00 0x00 0x2af8 0x11a8 0x3e8 0x01 0x00>;
					strategy_temp_normal_high = <0x2af8 0x118a 0x1388 0x00 0x00 0x2af8 0x118a 0x12c0 0x00 0x00 0x2af8 0x118a 0x1194 0x00 0x00 0x2af8 0x118a 0xfa0 0x00 0x00 0x2af8 0x118a 0xdac 0x00 0x00 0x2af8 0x118a 0xbb8 0x00 0x00 0x2af8 0x118a 0x9c4 0x00 0x00 0x2af8 0x118a 0x7d0 0x00 0x00 0x2af8 0x118a 0x5dc 0x00 0x00 0x2af8 0x1194 0x3e8 0x01 0x00>;
					strategy_temp_warm = <0x2af8 0x1018 0x708 0x00 0x00 0x2af8 0x1018 0x5dc 0x00 0x00 0x2af8 0x1022 0x3e8 0x01 0x00>;
				};
				
				strategy_soc_range_mid_low {
					strategy_temp_little_cold = <0x2af8 0x102c 0x4b0 0x00 0x00 0x2af8 0x1036 0x3e8 0x01 0x00>;
					strategy_temp_cool = <0x2af8 0xfe6 0x5dc 0x00 0x00 0x2af8 0xff0 0x3e8 0x01 0x00>;
					strategy_temp_little_cool = <0x2af8 0xff0 0xc80 0x00 0x00 0x2af8 0xff0 0xbb8 0x00 0x00 0x2af8 0xff0 0x9c4 0x00 0x00 0x2af8 0xff0 0x7d0 0x00 0x00 0x2af8 0x104a 0x5dc 0x00 0x00 0x2af8 0x1054 0x3e8 0x01 0x00>;
					strategy_temp_little_cool_high = <0x2af8 0xff0 0xed8 0x00 0x00 0x2af8 0xff0 0xdac 0x00 0x00 0x2af8 0x1054 0xc80 0x00 0x00 0x2af8 0x1054 0xbb8 0x00 0x00 0x2af8 0x1054 0x9c4 0x00 0x00 0x2af8 0x1054 0x7d0 0x00 0x00 0x2af8 0x119e 0x5dc 0x00 0x00 0x2af8 0x11a8 0x3e8 0x01 0x00>;
					strategy_temp_normal_low = <0x2af8 0x119e 0x1388 0x00 0x00 0x2af8 0x119e 0x12c0 0x00 0x00 0x2af8 0x119e 0x1194 0x00 0x00 0x2af8 0x119e 0xfa0 0x00 0x00 0x2af8 0x119e 0xdac 0x00 0x00 0x2af8 0x119e 0xbb8 0x00 0x00 0x2af8 0x119e 0x9c4 0x00 0x00 0x2af8 0x119e 0x7d0 0x00 0x00 0x2af8 0x119e 0x5dc 0x00 0x00 0x2af8 0x11a8 0x3e8 0x01 0x00>;
					strategy_temp_normal_high = <0x2af8 0x118a 0x1388 0x00 0x00 0x2af8 0x118a 0x12c0 0x00 0x00 0x2af8 0x118a 0x1194 0x00 0x00 0x2af8 0x118a 0xfa0 0x00 0x00 0x2af8 0x118a 0xdac 0x00 0x00 0x2af8 0x118a 0xbb8 0x00 0x00 0x2af8 0x118a 0x9c4 0x00 0x00 0x2af8 0x118a 0x7d0 0x00 0x00 0x2af8 0x118a 0x5dc 0x00 0x00 0x2af8 0x1194 0x3e8 0x01 0x00>;
					strategy_temp_warm = <0x2af8 0x1018 0x708 0x00 0x00 0x2af8 0x1018 0x5dc 0x00 0x00 0x2af8 0x1022 0x3e8 0x01 0x00>;
				};
				
				strategy_soc_range_mid {
					strategy_temp_little_cold = <0x2af8 0x102c 0x4b0 0x00 0x00 0x2af8 0x1036 0x3e8 0x01 0x00>;
					strategy_temp_cool = <0x2af8 0xfe6 0x5dc 0x00 0x00 0x2af8 0xff0 0x3e8 0x01 0x00>;
					strategy_temp_little_cool = <0x2af8 0xff0 0xbb8 0x00 0x00 0x2af8 0xff0 0x9c4 0x00 0x00 0x2af8 0xff0 0x7d0 0x00 0x00 0x2af8 0x104a 0x640 0x00 0x00 0x2af8 0x104a 0x5dc 0x00 0x00 0x2af8 0x1054 0x3e8 0x01 0x00>;
					strategy_temp_little_cool_high = <0x2af8 0x1054 0xbb8 0x00 0x00 0x2af8 0x1054 0x9c4 0x00 0x00 0x2af8 0x1054 0x7d0 0x00 0x00 0x2af8 0x119e 0x5dc 0x00 0x00 0x2af8 0x11a8 0x3e8 0x01 0x00>;
					strategy_temp_normal_low = <0x2af8 0x119e 0xdac 0x00 0x00 0x2af8 0x119e 0xbb8 0x00 0x00 0x2af8 0x119e 0x9c4 0x00 0x00 0x2af8 0x119e 0x7d0 0x00 0x00 0x2af8 0x119e 0x5dc 0x00 0x00 0x2af8 0x11a8 0x3e8 0x01 0x00>;
					strategy_temp_normal_high = <0x2af8 0x118a 0xfa0 0x00 0x00 0x2af8 0x118a 0xdac 0x00 0x00 0x2af8 0x118a 0xbb8 0x00 0x00 0x2af8 0x118a 0x9c4 0x00 0x00 0x2af8 0x118a 0x7d0 0x00 0x00 0x2af8 0x118a 0x5dc 0x00 0x00 0x2af8 0x1194 0x3e8 0x01 0x00>;
					strategy_temp_warm = <0x2af8 0x1018 0x76c 0x00 0x00 0x2af8 0x1018 0x5dc 0x00 0x00 0x2af8 0x1022 0x3e8 0x01 0x00>;
				};
				
				strategy_soc_range_mid_high {
					strategy_temp_little_cold = <0x2af8 0x102c 0x4b0 0x00 0x00 0x2af8 0x1036 0x3e8 0x01 0x00>;
					strategy_temp_cool = <0x2af8 0xfe6 0x5dc 0x00 0x00 0x2af8 0xff0 0x3e8 0x01 0x00>;
					strategy_temp_little_cool = <0x2af8 0xff0 0x7d0 0x00 0x00 0x2af8 0x104a 0x5dc 0x00 0x00 0x2af8 0x1054 0x3e8 0x01 0x00>;
					strategy_temp_little_cool_high = <0x2af8 0x1054 0x7d0 0x00 0x00 0x2af8 0x119e 0x5dc 0x00 0x00 0x2af8 0x11a8 0x3e8 0x01 0x00>;
					strategy_temp_normal_low = <0x2af8 0x119e 0x9c4 0x00 0x00 0x2af8 0x119e 0x7d0 0x00 0x00 0x2af8 0x119e 0x5dc 0x00 0x00 0x2af8 0x11a8 0x3e8 0x01 0x00>;
					strategy_temp_normal_high = <0x2af8 0x118a 0x9c4 0x00 0x00 0x2af8 0x118a 0x7d0 0x00 0x00 0x2af8 0x118a 0x5dc 0x00 0x00 0x2af8 0x1194 0x3e8 0x01 0x00>;
					strategy_temp_warm = <0x2af8 0x1018 0x76c 0x00 0x00 0x2af8 0x1018 0x5dc 0x00 0x00 0x2af8 0x1022 0x3e8 0x01 0x00>;
				};
				
				strategy_soc_range_high {
					strategy_temp_little_cold = <0x2af8 0x1036 0x3e8 0x01 0x00>;
					strategy_temp_cool = <0x2af8 0x1194 0x3e8 0x01 0x00>;
					strategy_temp_little_cool = <0x2af8 0x1194 0x3e8 0x01 0x00>;
					strategy_temp_little_cool_high = <0x2af8 0x1194 0x3e8 0x01 0x00>;
					strategy_temp_normal_low = <0x2af8 0x1194 0x3e8 0x01 0x00>;
					strategy_temp_normal_high = <0x2af8 0x117b 0x3e8 0x01 0x00>;
					strategy_temp_warm = <0x2af8 0x1022 0x3e8 0x01 0x00>;
				};
			};
			
			pps_charge_oplus_strategy {
				oplus,temp_type = <0x01>;
				oplus,soc_range = <0x00 0x14 0x23 0x37 0x4b 0x55 0x63>;
				
				strategy_soc_range_min {
					strategy_temp_little_cold = <0x2af8 0x102c 0x4b0 0x00 0x00 0x2af8 0x1036 0x3e8 0x01 0x00>;
					strategy_temp_cool = <0x2af8 0xfe6 0x5dc 0x00 0x00 0x2af8 0xff0 0x3e8 0x01 0x00>;
					strategy_temp_little_cool = <0x2af8 0xff0 0xc80 0x00 0x00 0x2af8 0xff0 0xbb8 0x00 0x00 0x2af8 0xff0 0x9c4 0x00 0x00 0x2af8 0xff0 0x7d0 0x00 0x00 0x2af8 0x104a 0x5dc 0x00 0x00 0x2af8 0x1054 0x3e8 0x01 0x00>;
					strategy_temp_little_cool_high = <0x2af8 0xff0 0xed8 0x00 0x00 0x2af8 0xff0 0xdac 0x00 0x00 0x2af8 0x1054 0xc80 0x00 0x00 0x2af8 0x1054 0xbb8 0x00 0x00 0x2af8 0x1054 0x9c4 0x00 0x00 0x2af8 0x1054 0x7d0 0x00 0x00 0x2af8 0x119e 0x5dc 0x00 0x00 0x2af8 0x11a8 0x3e8 0x01 0x00>;
					strategy_temp_normal_low = <0x2af8 0x119e 0x1388 0x00 0x00 0x2af8 0x119e 0x12c0 0x00 0x00 0x2af8 0x119e 0x1194 0x00 0x00 0x2af8 0x119e 0xfa0 0x00 0x00 0x2af8 0x119e 0xdac 0x00 0x00 0x2af8 0x119e 0xbb8 0x00 0x00 0x2af8 0x119e 0x9c4 0x00 0x00 0x2af8 0x119e 0x7d0 0x00 0x00 0x2af8 0x119e 0x5dc 0x00 0x00 0x2af8 0x11a8 0x3e8 0x01 0x00>;
					strategy_temp_normal_high = <0x2af8 0x118a 0x1388 0x00 0x00 0x2af8 0x118a 0x12c0 0x00 0x00 0x2af8 0x118a 0x1194 0x00 0x00 0x2af8 0x118a 0xfa0 0x00 0x00 0x2af8 0x118a 0xdac 0x00 0x00 0x2af8 0x118a 0xbb8 0x00 0x00 0x2af8 0x118a 0x9c4 0x00 0x00 0x2af8 0x118a 0x7d0 0x00 0x00 0x2af8 0x118a 0x5dc 0x00 0x00 0x2af8 0x1194 0x3e8 0x01 0x00>;
					strategy_temp_warm = <0x2af8 0x1018 0x708 0x00 0x00 0x2af8 0x1018 0x5dc 0x00 0x00 0x2af8 0x1022 0x3e8 0x01 0x00>;
				};
				
				strategy_soc_range_low {
					strategy_temp_little_cold = <0x2af8 0x102c 0x4b0 0x00 0x00 0x2af8 0x1036 0x3e8 0x01 0x00>;
					strategy_temp_cool = <0x2af8 0xfe6 0x5dc 0x00 0x00 0x2af8 0xff0 0x3e8 0x01 0x00>;
					strategy_temp_little_cool = <0x2af8 0xff0 0xc80 0x00 0x00 0x2af8 0xff0 0xbb8 0x00 0x00 0x2af8 0xff0 0x9c4 0x00 0x00 0x2af8 0xff0 0x7d0 0x00 0x00 0x2af8 0x104a 0x5dc 0x00 0x00 0x2af8 0x1054 0x3e8 0x01 0x00>;
					strategy_temp_little_cool_high = <0x2af8 0xff0 0xed8 0x00 0x00 0x2af8 0xff0 0xdac 0x00 0x00 0x2af8 0x1054 0xc80 0x00 0x00 0x2af8 0x1054 0xbb8 0x00 0x00 0x2af8 0x1054 0x9c4 0x00 0x00 0x2af8 0x1054 0x7d0 0x00 0x00 0x2af8 0x119e 0x5dc 0x00 0x00 0x2af8 0x11a8 0x3e8 0x01 0x00>;
					strategy_temp_normal_low = <0x2af8 0x119e 0x1388 0x00 0x00 0x2af8 0x119e 0x12c0 0x00 0x00 0x2af8 0x119e 0x1194 0x00 0x00 0x2af8 0x119e 0xfa0 0x00 0x00 0x2af8 0x119e 0xdac 0x00 0x00 0x2af8 0x119e 0xbb8 0x00 0x00 0x2af8 0x119e 0x9c4 0x00 0x00 0x2af8 0x119e 0x7d0 0x00 0x00 0x2af8 0x119e 0x5dc 0x00 0x00 0x2af8 0x11a8 0x3e8 0x01 0x00>;
					strategy_temp_normal_high = <0x2af8 0x118a 0x1388 0x00 0x00 0x2af8 0x118a 0x12c0 0x00 0x00 0x2af8 0x118a 0x1194 0x00 0x00 0x2af8 0x118a 0xfa0 0x00 0x00 0x2af8 0x118a 0xdac 0x00 0x00 0x2af8 0x118a 0xbb8 0x00 0x00 0x2af8 0x118a 0x9c4 0x00 0x00 0x2af8 0x118a 0x7d0 0x00 0x00 0x2af8 0x118a 0x5dc 0x00 0x00 0x2af8 0x1194 0x3e8 0x01 0x00>;
					strategy_temp_warm = <0x2af8 0x1018 0x708 0x00 0x00 0x2af8 0x1018 0x5dc 0x00 0x00 0x2af8 0x1022 0x3e8 0x01 0x00>;
				};
				
				strategy_soc_range_mid_low {
					strategy_temp_little_cold = <0x2af8 0x102c 0x4b0 0x00 0x00 0x2af8 0x1036 0x3e8 0x01 0x00>;
					strategy_temp_cool = <0x2af8 0xfe6 0x5dc 0x00 0x00 0x2af8 0xff0 0x3e8 0x01 0x00>;
					strategy_temp_little_cool = <0x2af8 0xff0 0xc80 0x00 0x00 0x2af8 0xff0 0xbb8 0x00 0x00 0x2af8 0xff0 0x9c4 0x00 0x00 0x2af8 0xff0 0x7d0 0x00 0x00 0x2af8 0x104a 0x5dc 0x00 0x00 0x2af8 0x1054 0x3e8 0x01 0x00>;
					strategy_temp_little_cool_high = <0x2af8 0xff0 0xed8 0x00 0x00 0x2af8 0xff0 0xdac 0x00 0x00 0x2af8 0x1054 0xc80 0x00 0x00 0x2af8 0x1054 0xbb8 0x00 0x00 0x2af8 0x1054 0x9c4 0x00 0x00 0x2af8 0x1054 0x7d0 0x00 0x00 0x2af8 0x119e 0x5dc 0x00 0x00 0x2af8 0x11a8 0x3e8 0x01 0x00>;
					strategy_temp_normal_low = <0x2af8 0x119e 0x1388 0x00 0x00 0x2af8 0x119e 0x12c0 0x00 0x00 0x2af8 0x119e 0x1194 0x00 0x00 0x2af8 0x119e 0xfa0 0x00 0x00 0x2af8 0x119e 0xdac 0x00 0x00 0x2af8 0x119e 0xbb8 0x00 0x00 0x2af8 0x119e 0x9c4 0x00 0x00 0x2af8 0x119e 0x7d0 0x00 0x00 0x2af8 0x119e 0x5dc 0x00 0x00 0x2af8 0x11a8 0x3e8 0x01 0x00>;
					strategy_temp_normal_high = <0x2af8 0x118a 0x1388 0x00 0x00 0x2af8 0x118a 0x12c0 0x00 0x00 0x2af8 0x118a 0x1194 0x00 0x00 0x2af8 0x118a 0xfa0 0x00 0x00 0x2af8 0x118a 0xdac 0x00 0x00 0x2af8 0x118a 0xbb8 0x00 0x00 0x2af8 0x118a 0x9c4 0x00 0x00 0x2af8 0x118a 0x7d0 0x00 0x00 0x2af8 0x118a 0x5dc 0x00 0x00 0x2af8 0x1194 0x3e8 0x01 0x00>;
					strategy_temp_warm = <0x2af8 0x1018 0x708 0x00 0x00 0x2af8 0x1018 0x5dc 0x00 0x00 0x2af8 0x1022 0x3e8 0x01 0x00>;
				};
				
				strategy_soc_range_mid {
					strategy_temp_little_cold = <0x2af8 0x102c 0x4b0 0x00 0x00 0x2af8 0x1036 0x3e8 0x01 0x00>;
					strategy_temp_cool = <0x2af8 0xfe6 0x5dc 0x00 0x00 0x2af8 0xff0 0x3e8 0x01 0x00>;
					strategy_temp_little_cool = <0x2af8 0xff0 0xbb8 0x00 0x00 0x2af8 0xff0 0x9c4 0x00 0x00 0x2af8 0xff0 0x7d0 0x00 0x00 0x2af8 0x104a 0x640 0x00 0x00 0x2af8 0x104a 0x5dc 0x00 0x00 0x2af8 0x1054 0x3e8 0x01 0x00>;
					strategy_temp_little_cool_high = <0x2af8 0x1054 0xbb8 0x00 0x00 0x2af8 0x1054 0x9c4 0x00 0x00 0x2af8 0x1054 0x7d0 0x00 0x00 0x2af8 0x119e 0x5dc 0x00 0x00 0x2af8 0x11a8 0x3e8 0x01 0x00>;
					strategy_temp_normal_low = <0x2af8 0x119e 0xdac 0x00 0x00 0x2af8 0x119e 0xbb8 0x00 0x00 0x2af8 0x119e 0x9c4 0x00 0x00 0x2af8 0x119e 0x7d0 0x00 0x00 0x2af8 0x119e 0x5dc 0x00 0x00 0x2af8 0x11a8 0x3e8 0x01 0x00>;
					strategy_temp_normal_high = <0x2af8 0x118a 0xfa0 0x00 0x00 0x2af8 0x118a 0xdac 0x00 0x00 0x2af8 0x118a 0xbb8 0x00 0x00 0x2af8 0x118a 0x9c4 0x00 0x00 0x2af8 0x118a 0x7d0 0x00 0x00 0x2af8 0x118a 0x5dc 0x00 0x00 0x2af8 0x1194 0x3e8 0x01 0x00>;
					strategy_temp_warm = <0x2af8 0x1018 0x76c 0x00 0x00 0x2af8 0x1018 0x5dc 0x00 0x00 0x2af8 0x1022 0x3e8 0x01 0x00>;
				};
				
				strategy_soc_range_mid_high {
					strategy_temp_little_cold = <0x2af8 0x102c 0x4b0 0x00 0x00 0x2af8 0x1036 0x3e8 0x01 0x00>;
					strategy_temp_cool = <0x2af8 0xfe6 0x5dc 0x00 0x00 0x2af8 0xff0 0x3e8 0x01 0x00>;
					strategy_temp_little_cool = <0x2af8 0xff0 0x7d0 0x00 0x00 0x2af8 0x104a 0x5dc 0x00 0x00 0x2af8 0x1054 0x3e8 0x01 0x00>;
					strategy_temp_little_cool_high = <0x2af8 0x1054 0x7d0 0x00 0x00 0x2af8 0x119e 0x5dc 0x00 0x00 0x2af8 0x11a8 0x3e8 0x01 0x00>;
					strategy_temp_normal_low = <0x2af8 0x119e 0x9c4 0x00 0x00 0x2af8 0x119e 0x7d0 0x00 0x00 0x2af8 0x119e 0x5dc 0x00 0x00 0x2af8 0x11a8 0x3e8 0x01 0x00>;
					strategy_temp_normal_high = <0x2af8 0x118a 0x9c4 0x00 0x00 0x2af8 0x118a 0x7d0 0x00 0x00 0x2af8 0x118a 0x5dc 0x00 0x00 0x2af8 0x1194 0x3e8 0x01 0x00>;
					strategy_temp_warm = <0x2af8 0x1018 0x76c 0x00 0x00 0x2af8 0x1018 0x5dc 0x00 0x00 0x2af8 0x1022 0x3e8 0x01 0x00>;
				};
				
				strategy_soc_range_high {
					strategy_temp_little_cold = <0x2af8 0x1036 0x3e8 0x01 0x00>;
					strategy_temp_cool = <0x2af8 0x1194 0x3e8 0x01 0x00>;
					strategy_temp_little_cool = <0x2af8 0x1194 0x3e8 0x01 0x00>;
					strategy_temp_little_cool_high = <0x2af8 0x1194 0x3e8 0x01 0x00>;
					strategy_temp_normal_low = <0x2af8 0x1194 0x3e8 0x01 0x00>;
					strategy_temp_normal_high = <0x2af8 0x117b 0x3e8 0x01 0x00>;
					strategy_temp_warm = <0x2af8 0x1022 0x3e8 0x01 0x00>;
				};
			};
		};
	};
};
